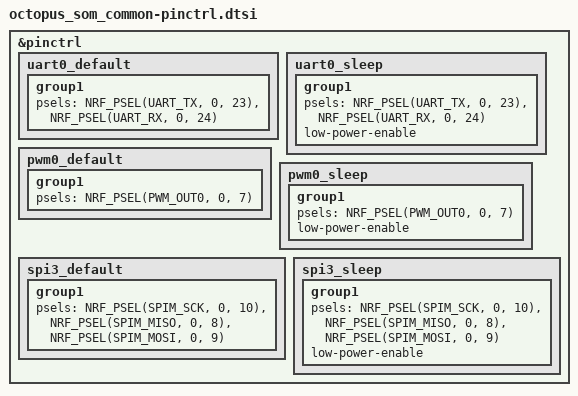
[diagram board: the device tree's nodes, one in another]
/*
 * Copyright (c) 2024 Norik Systems
 * SPDX-License-Identifier: Apache-2.0
 */

&pinctrl {
	uart0_default: uart0_default {
		group1 {
			psels = <NRF_PSEL(UART_TX, 0, 23)>,
				<NRF_PSEL(UART_RX, 0, 24)>;
		};
	};

	uart0_sleep: uart0_sleep {
		group1 {
			psels = <NRF_PSEL(UART_TX, 0, 23)>,
				<NRF_PSEL(UART_RX, 0, 24)>;
			low-power-enable;
		};
	};

	pwm0_default: pwm0_default {
		group1 {
			psels = <NRF_PSEL(PWM_OUT0, 0, 7)>;
		};
	};

	pwm0_sleep: pwm0_sleep {
		group1 {
			psels = <NRF_PSEL(PWM_OUT0, 0, 7)>;
			low-power-enable;
		};
	};

	spi3_default: spi3_default {
		group1 {
			psels = <NRF_PSEL(SPIM_SCK, 0, 10)>,
					<NRF_PSEL(SPIM_MISO, 0, 8)>,
					<NRF_PSEL(SPIM_MOSI, 0, 9)>;
		};
	};

	spi3_sleep: spi3_sleep {
		group1 {
			psels = <NRF_PSEL(SPIM_SCK, 0, 10)>,
					<NRF_PSEL(SPIM_MISO, 0, 8)>,
					<NRF_PSEL(SPIM_MOSI, 0, 9)>;
			low-power-enable;
		};
	};
};
